AUTOSAR XML (schema 00048)
package /HuaweiMDC/FunctionalSoftware/Mapping/Execution
  executable MappingExecutable
    root sw component prototype MappingRootSwComponent: application-type=MappingApplicationSwComponent
package /HuaweiMDC/FunctionalSoftware/Mapping/SwComponent
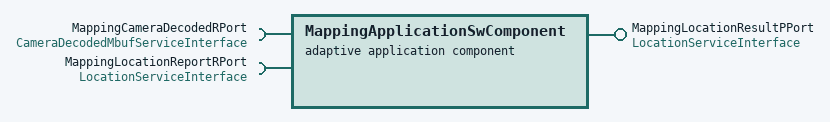
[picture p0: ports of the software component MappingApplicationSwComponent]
  adaptive application sw component type MappingApplicationSwComponent
    require port MappingCameraDecodedRPort: required-interface=CameraDecodedMbufServiceInterface
    require port MappingLocationReportRPort: required-interface=LocationServiceInterface
    provide port MappingLocationResultPPort: provided-interface=LocationServiceInterface
